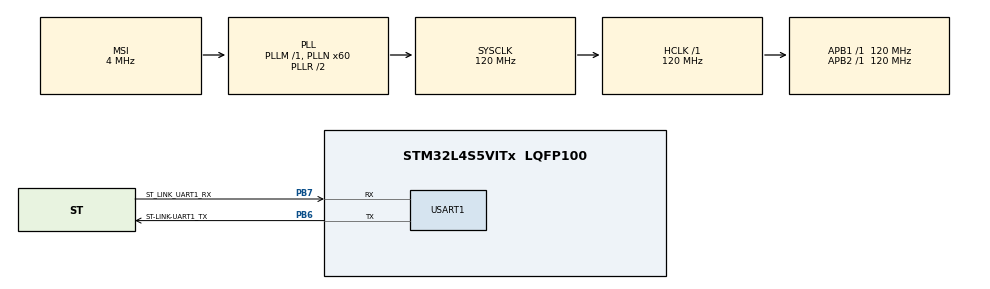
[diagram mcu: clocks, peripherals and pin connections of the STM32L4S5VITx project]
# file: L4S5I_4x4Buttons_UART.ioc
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Mcu.Family=STM32L4
Mcu.Name=STM32L4S5VITx
Mcu.Package=LQFP100
NVIC.PriorityGroup=NVIC_PRIORITYGROUP_4
PB6.GPIO_Label=ST-LINK-UART1_TX
PB6.Mode=Asynchronous
PB6.Signal=USART1_TX
PB7.GPIO_Label=ST_LINK_UART1_RX
PB7.Mode=Asynchronous
PB7.Signal=USART1_RX
ProjectManager.HeapSize=0x200
ProjectManager.StackSize=0x400
ProjectManager.TargetToolchain=STM32CubeIDE
RCC.ADCFreq_Value=48000000
RCC.AHBFreq_Value=120000000
RCC.APB1Freq_Value=120000000
RCC.APB1TimFreq_Value=120000000
RCC.APB2Freq_Value=120000000
RCC.APB2TimFreq_Value=120000000
RCC.CortexFreq_Value=120000000
RCC.HCLKFreq_Value=120000000
RCC.HSE_VALUE=8000000
RCC.HSI48_VALUE=48000000
RCC.HSI_VALUE=16000000
RCC.MSI_VALUE=4000000
RCC.PLLN=60
RCC.PLLSAI1N=24
RCC.SYSCLKFreq_VALUE=120000000
RCC.SYSCLKSource=RCC_SYSCLKSOURCE_PLLCLK
RCC.USBFreq_Value=48000000
RCC.VCOOutputFreq_Value=240000000
USART1.VirtualMode-Asynchronous=VM_ASYNC
board=B-L4S5I-IOT01A

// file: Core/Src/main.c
/* USER CODE BEGIN Header */
/**
  ******************************************************************************
  * @file           : main.c
  * @brief          : Main program body
  ******************************************************************************
  * @attention
  *
  * Copyright (c) 2025 STMicroelectronics.
  * All rights reserved.
  *
  * This software is licensed under terms that can be found in the LICENSE file
  * in the root directory of this software component.
  * If no LICENSE file comes with this software, it is provided AS-IS.
  *
  ******************************************************************************
  */
/* USER CODE END Header */
#include "main.h"

/* USER CODE BEGIN Includes */
#include <stdio.h>
#include "retarget.h"
/* USER CODE END Includes */

/* USER CODE BEGIN PD */
#define DEBOUNCE_MS 25
/* USER CODE END PD */

UART_HandleTypeDef huart1;

void SystemClock_Config(void);
static void MX_GPIO_Init(void);
static void MX_USART1_UART_Init(void);

/* USER CODE BEGIN 0 */
/**
 * Buttons	R4	R3	R2	R1	C1	C2	C3	C4
 * Arduino	D4	D10	D0	D1	A5	A4	A3	A2
 * GPIO		A3	A2	A1	A0	C0	C1	C2	C3
 */
uint8_t getKeypad(void)
{
	uint32_t key=0;
	/* GPIOA are rows */
	GPIOA->MODER &= ~0xFF; //SET ROWS INPUT with PULLUP
	/* GPIOC are cols */
	GPIOC->MODER = (GPIOC->MODER & ~0xFF) | 0x55; //SET_COLS_OUTPUT

	GPIOC->BSRR = 0xF<<16; //OUTPUT_LOW_ON_COLS

	HAL_Delay(1); // propagation delay

	key = (GPIOA->IDR & 0xF)<<4; // readRowsOfPortA

	GPIOC->MODER &= ~0xFF; //	SET_COLS_INPUT_PULLUP

	GPIOA->MODER = (GPIOA->MODER & ~0xFF) | 0x55; //	SET_ROWS_OUTPUT

	GPIOA->BSRR = 0xF<<16; //	OUTPUT_LOW_ON_ROWS

	HAL_Delay(1);

	key |= GPIOC->IDR & 0xF; // readColsOfPortC
	return (uint8_t)(~key);
}

uint8_t decodeKey(uint8_t key)
{
	uint8_t decoded;
	switch (key) {
		case 0x11:
			decoded=1;
			break;
		case 0x12:
			decoded=2;
			break;
		case 0x14:
			decoded=3;
			break;
		case 0x18:
			decoded=4;
			break;
		case 0x21:
			decoded=5;
			break;
		case 0x22:
			decoded=6;
			break;
		case 0x24:
			decoded=7;
			break;
		case 0x28:
			decoded=8;
			break;
		case 0x41:
			decoded=9;
			break;
		case 0x42:
			decoded=10;
			break;
		case 0x44:
			decoded=11;
			break;
		case 0x48:
			decoded=12;
			break;
		case 0x81:
			decoded=13;
			break;
		case 0x82:
			decoded=14;
			break;
		case 0x84:
			decoded=15;
			break;
		case 0x88:
			decoded=16;
			break;
		default:
			decoded=99;
			break;
	}
	return decoded;
}
/* USER CODE END 0 */

int main(void)
{

  /* MCU Configuration--------------------------------------------------------*/

  /* Reset of all peripherals, Initializes the Flash interface and the Systick. */
  HAL_Init();

  /* Configure the system clock */
  SystemClock_Config();

  /* Initialize all configured peripherals */
  MX_GPIO_Init();
  MX_USART1_UART_Init();
  /* USER CODE BEGIN 2 */
  RetargetInit(&huart1);
  RCC->AHB2ENR |= 5; // enable GPIOC and GPIOA
  uint32_t timeStamp = HAL_GetTick();
  /* set pins 0-3 to pull-up on GPIOC and GPIOA*/
  GPIOC->PUPDR |= 0x55;
  GPIOA->PUPDR |= 0x55;
  uint8_t tmpKey;
  /* USER CODE END 2 */

  /* Infinite loop */
  while (1)
  {
	if((tmpKey = getKeypad()) != 0)
	  {
		  HAL_Delay(DEBOUNCE_MS);
		  if(tmpKey == getKeypad())
		  {
			  /*wait for the keys release*/
			  timeStamp = HAL_GetTick();
			  while(HAL_GetTick() - timeStamp < DEBOUNCE_MS) if(getKeypad() != 0) timeStamp = HAL_GetTick();
			  uint8_t decoded = decodeKey(tmpKey);
			  if(decoded<=16)
				  printf("-> %lu\t%x\t%u\r\n", HAL_GetTick(), tmpKey, decoded);
			  else
				  printf("-> %lu\t%x\tUnknown\r\n", HAL_GetTick(), tmpKey);
		  }
	  }
  }
}

void SystemClock_Config(void)
{
  RCC_OscInitTypeDef RCC_OscInitStruct = {0};
  RCC_ClkInitTypeDef RCC_ClkInitStruct = {0};

  /** Configure the main internal regulator output voltage
  */
  if (HAL_PWREx_ControlVoltageScaling(PWR_REGULATOR_VOLTAGE_SCALE1_BOOST) != HAL_OK)
  {
    Error_Handler();
  }

  /** Initializes the RCC Oscillators according to the specified parameters
  * in the RCC_OscInitTypeDef structure.
  */
  RCC_OscInitStruct.OscillatorType = RCC_OSCILLATORTYPE_MSI;
  RCC_OscInitStruct.MSIState = RCC_MSI_ON;
  RCC_OscInitStruct.MSICalibrationValue = 0;
  RCC_OscInitStruct.MSIClockRange = RCC_MSIRANGE_6;
  RCC_OscInitStruct.PLL.PLLState = RCC_PLL_ON;
  RCC_OscInitStruct.PLL.PLLSource = RCC_PLLSOURCE_MSI;
  RCC_OscInitStruct.PLL.PLLM = 1;
  RCC_OscInitStruct.PLL.PLLN = 60;
  RCC_OscInitStruct.PLL.PLLP = RCC_PLLP_DIV2;
  RCC_OscInitStruct.PLL.PLLQ = RCC_PLLQ_DIV2;
  RCC_OscInitStruct.PLL.PLLR = RCC_PLLR_DIV2;
  if (HAL_RCC_OscConfig(&RCC_OscInitStruct) != HAL_OK)
  {
    Error_Handler();
  }

  /** Initializes the CPU, AHB and APB buses clocks
  */
  RCC_ClkInitStruct.ClockType = RCC_CLOCKTYPE_HCLK|RCC_CLOCKTYPE_SYSCLK
                              |RCC_CLOCKTYPE_PCLK1|RCC_CLOCKTYPE_PCLK2;
  RCC_ClkInitStruct.SYSCLKSource = RCC_SYSCLKSOURCE_PLLCLK;
  RCC_ClkInitStruct.AHBCLKDivider = RCC_SYSCLK_DIV1;
  RCC_ClkInitStruct.APB1CLKDivider = RCC_HCLK_DIV1;
  RCC_ClkInitStruct.APB2CLKDivider = RCC_HCLK_DIV1;

  if (HAL_RCC_ClockConfig(&RCC_ClkInitStruct, FLASH_LATENCY_5) != HAL_OK)
  {
    Error_Handler();
  }
}

static void MX_USART1_UART_Init(void)
{

  huart1.Instance = USART1;
  huart1.Init.BaudRate = 115200;
  huart1.Init.WordLength = UART_WORDLENGTH_8B;
  huart1.Init.StopBits = UART_STOPBITS_1;
  huart1.Init.Parity = UART_PARITY_NONE;
  huart1.Init.Mode = UART_MODE_TX_RX;
  huart1.Init.HwFlowCtl = UART_HWCONTROL_NONE;
  huart1.Init.OverSampling = UART_OVERSAMPLING_16;
  huart1.Init.OneBitSampling = UART_ONE_BIT_SAMPLE_DISABLE;
  huart1.Init.ClockPrescaler = UART_PRESCALER_DIV1;
  huart1.AdvancedInit.AdvFeatureInit = UART_ADVFEATURE_NO_INIT;
  if (HAL_UART_Init(&huart1) != HAL_OK)
  {
    Error_Handler();
  }
  if (HAL_UARTEx_SetTxFifoThreshold(&huart1, UART_TXFIFO_THRESHOLD_1_8) != HAL_OK)
  {
    Error_Handler();
  }
  if (HAL_UARTEx_SetRxFifoThreshold(&huart1, UART_RXFIFO_THRESHOLD_1_8) != HAL_OK)
  {
    Error_Handler();
  }
  if (HAL_UARTEx_DisableFifoMode(&huart1) != HAL_OK)
  {
    Error_Handler();
  }

}

static void MX_GPIO_Init(void)
{

  /* GPIO Ports Clock Enable */
  __HAL_RCC_GPIOB_CLK_ENABLE();

}

void Error_Handler(void)
{
  __disable_irq();
  while (1)
  {
  }
}
